# ESP32-C5-LP register map
Vendor: ESPRESSIF SYSTEMS (SHANGHAI) CO., LTD.; Series: ESP32 C-Series; File version: 1
CPU: RV32IMAC r0p0, little endian, no MPU, no FPU, 0 interrupt priority bits
Address unit: 32 bits
Registers are 32-bit, read-write, reset 0x0 unless marked. A register's access mark holds for its fields unless they carry their own. Offsets are from the block's base; [hi:lo] are bit positions.

## LP_CLKRST — LP_CLKRST Peripheral
Base 0x600B0400
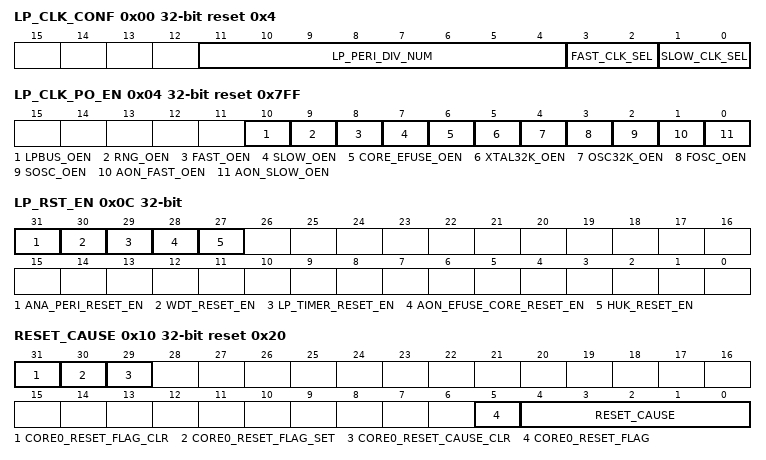
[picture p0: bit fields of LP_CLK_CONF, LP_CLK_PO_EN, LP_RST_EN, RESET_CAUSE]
0x00 LP_CLK_CONF reset 0x4 — Configures the root clk of LP system
  [11:4] LP_PERI_DIV_NUM — reserved
  [3:2] FAST_CLK_SEL — configures the source of LP_FAST_CLK. 0: RC_FAST_CLK 1: XTAL_D2_CLK 2: XTAL_CLK
  [1:0] SLOW_CLK_SEL — Configures the source of LP_SLOW_CLK. 0: RC_SLOW_CLK 1: XTAL32K_CLK 2: RC32K_CLK 3:OSC_SLOW_CLK
0x04 LP_CLK_PO_EN reset 0x7FF — Configures the clk gate to pad
  [10] LPBUS_OEN — Configures the clock gate to pad of the LP bus clk. 0: Disable the clk pass clock gate 1: Enable the clk pass clock gate
  [9] RNG_OEN — Configures the clock gate to pad of the RNG clk. 0: Disable the clk pass clock gate 1: Enable the clk pass clock gate
  [8] FAST_OEN — Configures the clock gate to pad of the LP_FAST_CLK. 0: Disable the clk pass clock gate 1: Enable the clk pass clock gate
  [7] SLOW_OEN — Configures the clock gate to pad of the LP_SLOW_CLK. 0: Disable the clk pass clock gate 1: Enable the clk pass clock gate
  [6] CORE_EFUSE_OEN — Configures the clock gate to pad of the EFUSE_CTRL clock. 0: Disable the clk pass clock gate 1: Enable the clk pass clock gate
  [5] XTAL32K_OEN — Configures the clock gate to pad of the XTAL32K_CLK. 0: Disable the clk pass clock gate 1: Enable the clk pass clock gate
  [4] OSC32K_OEN — Configures the clock gate to pad of the RC32K_CLK. 0: Disable the clk pass clock gate 1: Enable the clk pass clock gate
  [3] FOSC_OEN — Configures the clock gate to pad of the RC_FAST_CLK. 0: Disable the clk pass clock gate 1: Enable the clk pass clock gate
  [2] SOSC_OEN — Configures the clock gate to pad of the OSC_SLOW_CLK. 0: Disable the clk pass clock gate 1: Enable the clk pass clock gate
  [1] AON_FAST_OEN — Configures the clock gate to pad of the LP_DYN_FAST_CLK. 0: Disable the clk pass clock gate 1: Enable the clk pass clock gate
  [0] AON_SLOW_OEN — Configures the clock gate to pad of the LP_DYN_SLOW_CLK. 0: Disable the clk pass clock gate 1: Enable the clk pass clock gate
0x08 LP_CLK_EN — Configure LP root clk source gate
  [31] FAST_ORI_GATE — Configures the clock gate to LP_FAST_CLK 0: Invalid. The clock gate controlled by hardware fsm 1: Force the clk pass clock gate
0x0C LP_RST_EN — Configures the peri of LP system software reset
  [31] ANA_PERI_RESET_EN — Configures whether or not to reset analog peri, include brownout controller 0: Invalid.No effect 1: Reset
  [30] WDT_RESET_EN — Configures whether or not to reset LP_WDT and super watch dog 0: Invalid.No effect 1: Reset
  [29] LP_TIMER_RESET_EN — Configures whether or not to reset LP_TIMER 0: Invalid.No effect 1: Reset
  [28] AON_EFUSE_CORE_RESET_EN — Configures whether or not to reset EFUSE_CTRL always-on part 0: Invalid.No effect 1: Reset
  [27] HUK_RESET_EN — Configures whether or not to reset HUK 0: Invalid.No effect 1: Reset
0x10 RESET_CAUSE access per field reset 0x20 — Represents the reset casue
  [31] CORE0_RESET_FLAG_CLR wo — configure clear reset flag 0: no operation 1: clear flag to 0
  [30] CORE0_RESET_FLAG_SET wo — configure set reset flag
  [29] CORE0_RESET_CAUSE_CLR wo — 0: no operation
  [5] CORE0_RESET_FLAG ro — Represents the reset flag
  [4:0] RESET_CAUSE ro — Represents the reset cause
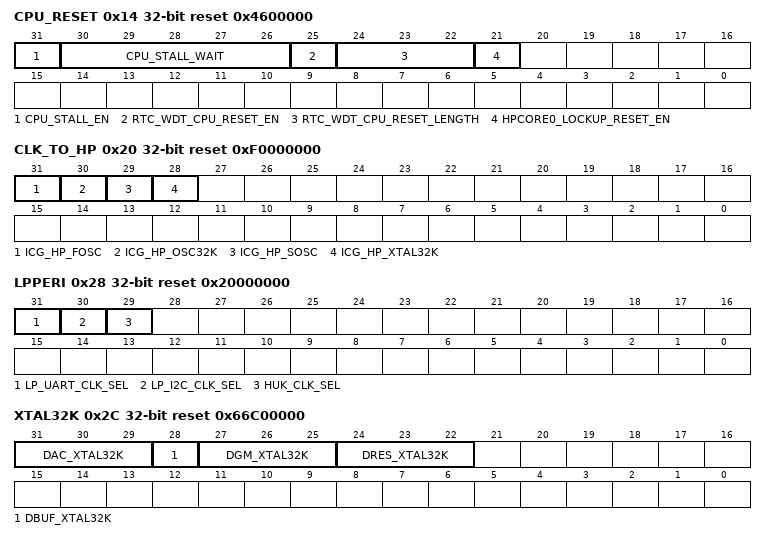
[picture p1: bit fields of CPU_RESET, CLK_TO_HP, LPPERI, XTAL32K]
0x14 CPU_RESET reset 0x4600000 — Configures CPU reset
  [31] CPU_STALL_EN — Configures whether or not CPU entry stall state before LP_WDT and software reset CPU 0: CPU will not entry stall state before LP_WDT and software reset CPU 1: CPU will entry stall state before LP_WDT and software reset CPU
  [30:26] CPU_STALL_WAIT — configure the time between CPU stall and reset Measurement unit: LP_DYN_FAST_CLK
  [25] RTC_WDT_CPU_RESET_EN — Configures whether or not LP_WDT can reset CPU 0: LP_WDT could not reset CPU when LP_WDT timeout 1: LP_WDT could reset CPU when LP_WDT timeout
  [24:22] RTC_WDT_CPU_RESET_LENGTH — configures the reset length of LP_WDT reset CPU Measurement unit: LP_DYN_FAST_CLK
  [21] HPCORE0_LOCKUP_RESET_EN — configure the hpcore0 luckup reset enable 0: disable 1:enable
0x18 FOSC_CNTL reset 0x2B000000 — Configures the RC_FAST_CLK frequency
  [31:22] FOSC_DFREQ — Configures the RC_FAST_CLK frequency,the clock frequency will increase with this field
0x1C RC32K_CNTL reset 0x2B000000 — Configures the RC32K_CLK frequency
  [31:22] RC32K_DFREQ — Configures the RC32K_CLK frequency, the clock frequency will increase with this field
0x20 CLK_TO_HP reset 0xF0000000 — Configures the clk gate of LP clk to HP system
  [31] ICG_HP_FOSC — Configures the clk gate of RC_FAST_CLK to HP system 0: The clk could not pass to HP system 1: The clk could pass to HP system
  [30] ICG_HP_OSC32K — Configures the clk gate of RC32K_CLK to HP system 0: The clk could not pass to HP system 1: The clk could pass to HP system
  [29] ICG_HP_SOSC — Configures the clk gate of RC_SLOW_CLK to HP system 0: The clk could not pass to HP system 1: The clk could pass to HP system
  [28] ICG_HP_XTAL32K — Configures the clk gate of XTAL32K_CLK to HP system 0: The clk could not pass to HP system 1: The clk could pass to HP system
0x24 LPMEM_FORCE — Configures the LP_MEM clk gate force parameter
  [31] LPMEM_CLK_FORCE_ON — Configures whether ot not force open the clock gate of LP MEM 0: Invalid. The clock gate controlled by hardware FSM 1: Force open clock gate of LP MEM
0x28 LPPERI reset 0x20000000 — Configures the LP peri clk
  [31] LP_UART_CLK_SEL — Configures the source clk of LP UART. 0: LP_FAST_CLK 1: XTAL_D2_CLK
  [30] LP_I2C_CLK_SEL — Configures the source clk of LP I2C. 0: LP_FAST_CLK 1: XTAL_D2_CLK
  [29] HUK_CLK_SEL — Configures the source clk of HUK 0: 0: RC_FAST_CLK 1: XTAL_D2_CLK
0x2C XTAL32K reset 0x66C00000 — Configures the XTAL32K parameter
  [31:29] DAC_XTAL32K — Configures DAC
  [28] DBUF_XTAL32K — Configures DBUF
  [27:25] DGM_XTAL32K — Configures DGM
  [24:22] DRES_XTAL32K — Configures DRES
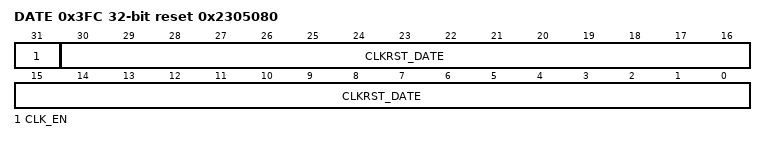
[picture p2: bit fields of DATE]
0x3FC DATE reset 0x2305080 — Version control register
  [31] CLK_EN — configure register clk bypass clk gate
  [30:0] CLKRST_DATE — Version control register
